AUTOSAR XML (schema 4-2-2)
package /ComponentTypes
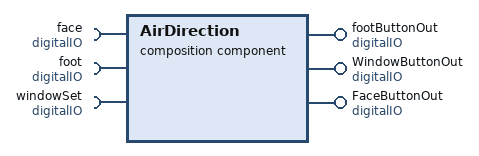
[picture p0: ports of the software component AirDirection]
  composition sw component type AirDirection
    require port face: required-interface=digitalIO
    require port foot: required-interface=digitalIO
    require port windowSet: required-interface=digitalIO
    provide port footButtonOut: provided-interface=digitalIO
    provide port WindowButtonOut: provided-interface=digitalIO
    provide port FaceButtonOut: provided-interface=digitalIO
    component Switch: type=Switch
    component SwitchOut: type=SwitchOut
    delegate SwitchOut.switchIn <-> outer port windowSet
    delegate SwitchOut.switchIn <-> outer port foot
    delegate SwitchOut.switchIn <-> outer port face
    delegate Switch.DialSet <-> outer port FaceButtonOut
    delegate Switch.DialSet <-> outer port WindowButtonOut
    delegate Switch.DialSet <-> outer port footButtonOut
